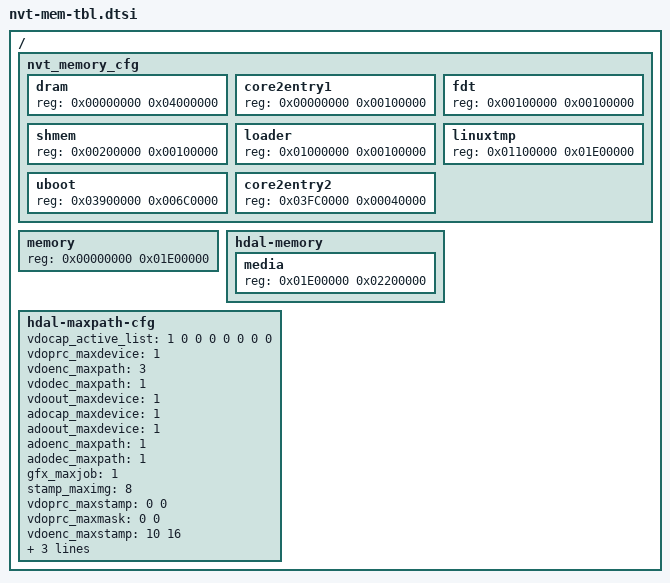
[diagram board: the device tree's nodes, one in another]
/*
 * Novatek Ltd. NA51089 BSP part of dts
 *
 * Cortex-A9
 *
 */
/ {
	/* Uboot/loader memory layout */
	nvt_memory_cfg {
		#address-cells = <1>;
		#size-cells = <1>;
		dram {          reg = <0x00000000 0x04000000>;  };
		core2entry1 {   reg = <0x00000000 0x00100000>;  };
		fdt {           reg = <0x00100000 0x00100000>;  };              /* recycled after linux started */
		shmem {         reg = <0x00200000 0x00100000>;  };              /* recycled after linux started */
		loader {        reg = <0x01000000 0x00100000>;  };              /* recycled after linux started */
		linuxtmp {      reg = <0x01100000 0x01E00000>;  };              /* recycled after linux started */
		uboot {         reg = <0x03900000 0x006C0000>;  };              /* recycled after linux started */
		core2entry2 {   reg = <0x03FC0000 0x00040000>;  };
	};
	/* Linux system memory region*/
	memory { device_type = "memory"; reg = <0x00000000 0x01E00000>; };

	hdal-memory {
		#address-cells = <1>;
		#size-cells = <1>;
		media { reg = <0x01E00000 0x02200000>; };
	};

	hdal-maxpath-cfg {
		/* First is for VCAP0, second for VCAP1 and so on.*/
		vdocap_active_list   = <1 0 0 0 0 0 0 0>;
		vdoprc_maxdevice   = <1>;
		vdoenc_maxpath   = <3>;
		vdodec_maxpath   = <1>;
		vdoout_maxdevice   = <1>;
		adocap_maxdevice   = <1>;
		adoout_maxdevice   = <1>;
		adoenc_maxpath   = <1>;
		adodec_maxpath   = <1>;
		/* gfx job list */
		gfx_maxjob       = <1>;
		/* stamp max img buffer number */
		stamp_maximg     = <8>;
		/* First is internal stamp number, second is external stamp number */
		vdoprc_maxstamp  = <0  0>;
		/* First is internal mask number, second is external mask number */
		vdoprc_maxmask   = <0  0>;
		vdoenc_maxstamp  = <10 16>;
		vdoenc_maxmask   = <0  8>;
		vdoout_maxstamp  = <0  0>;
		vdoout_maxmask   = <0  0>;
	};
};
